AUTOSAR XML (schema 4-0-3)
package /ComponentTypes
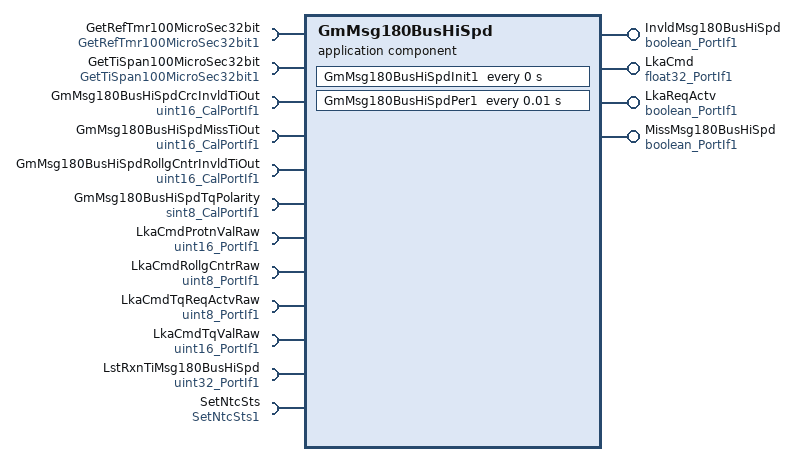
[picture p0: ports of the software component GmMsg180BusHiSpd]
  application sw component type GmMsg180BusHiSpd
    4 x provide port:
      InvldMsg180BusHiSpd: nonqueued-sender-com-spec{data-element=Logl, init-value=0}, provided-interface=boolean_PortIf1
      LkaCmd: nonqueued-sender-com-spec{data-element=Val, init-value=0}, provided-interface=float32_PortIf1
      LkaReqActv: nonqueued-sender-com-spec{data-element=Logl, init-value=0}, provided-interface=boolean_PortIf1
      MissMsg180BusHiSpd: nonqueued-sender-com-spec{data-element=Logl, init-value=0}, provided-interface=boolean_PortIf1
    12 x require port:
      GetRefTmr100MicroSec32bit: required-interface=GetRefTmr100MicroSec32bit1
      GetTiSpan100MicroSec32bit: required-interface=GetTiSpan100MicroSec32bit1
      GmMsg180BusHiSpdCrcInvldTiOut: parameter-require-com-spec{init-value=1000, parameter=Val}, required-interface=uint16_CalPortIf1
      GmMsg180BusHiSpdMissTiOut: parameter-require-com-spec{init-value=500, parameter=Val}, required-interface=uint16_CalPortIf1
      GmMsg180BusHiSpdRollgCntrInvldTiOut: parameter-require-com-spec{init-value=500, parameter=Val}, required-interface=uint16_CalPortIf1
      GmMsg180BusHiSpdTqPolarity: parameter-require-com-spec{init-value=1, parameter=Val}, required-interface=sint8_CalPortIf1
      LkaCmdProtnValRaw: nonqueued-receiver-com-spec{data-element=Val, filter=data-filter-type=ALWAYS, init-value=0}, required-interface=uint16_PortIf1
      LkaCmdRollgCntrRaw: nonqueued-receiver-com-spec{data-element=Val, filter=data-filter-type=ALWAYS, init-value=0}, required-interface=uint8_PortIf1
      LkaCmdTqReqActvRaw: nonqueued-receiver-com-spec{data-element=Val, filter=data-filter-type=ALWAYS, init-value=0}, required-interface=uint8_PortIf1
      LkaCmdTqValRaw: nonqueued-receiver-com-spec{data-element=Val, filter=data-filter-type=ALWAYS, init-value=0}, required-interface=uint16_PortIf1
      LstRxnTiMsg180BusHiSpd: nonqueued-receiver-com-spec{data-element=Val, filter=data-filter-type=ALWAYS, init-value=0}, required-interface=uint32_PortIf1
      SetNtcSts: required-interface=SetNtcSts1
    behavior GmMsg180BusHiSpd_InternalBehavior: data-type-mapping=Nexteer
      ar-typed-per-instance-memorys:
        8 x data, all with sw-calibration-access=READ-ONLY:
          GmMsg180BusHiSpdInvldCrcTmr: type=uint32
          GmMsg180BusHiSpdInvldRollgCntrTmr: type=uint32
          GmMsg180BusHiSpdPrevInvld: type=boolean
          GmMsg180BusHiSpdPrevRollgCntrVal: type=uint8
          GmMsg180BusHiSpdPrevRxnTi: type=uint32
          GmMsg180BusHiSpdPrevTqCmd: type=float32
          GmMsg180BusHiSpdPrevTqReq: type=boolean
          GmMsg180BusHiSpdRollgCntrRst: type=boolean
      timing event GmMsg180BusHiSpd_InitEvent: start-on-event=GmMsg180BusHiSpdInit1, period=0
      timing event TMT_GM0C9HSPer1: start-on-event=GmMsg180BusHiSpdPer1, period=0.01
      runnable GmMsg180BusHiSpdInit1
      runnable GmMsg180BusHiSpdPer1
        data-receive-point-by-arguments:
          5 x access:
            REC_LkaCmdProtnValRaw_Val: accessed-variable=LkaCmdProtnValRaw.Val
            REC_LkaCmdRollgCntrRaw_Val: accessed-variable=LkaCmdRollgCntrRaw.Val
            REC_LkaCmdTqReqActvRaw_Val: accessed-variable=LkaCmdTqReqActvRaw.Val
            REC_LkaCmdTqValRaw_Val: accessed-variable=LkaCmdTqValRaw.Val
            REC_Msg0C9HSLstRxnTi_Val: accessed-variable=LstRxnTiMsg180BusHiSpd.Val
        data-send-points:
          4 x access:
            SEND_InvldMsg180BusHiSpd_Logl: accessed-variable=InvldMsg180BusHiSpd.Logl
            SEND_LkaCmd_Val: accessed-variable=LkaCmd.Val
            SEND_LkaReqActv_Logl: accessed-variable=LkaReqActv.Logl
            SEND_MissMsg180BusHiSpd_Logl: accessed-variable=MissMsg180BusHiSpd.Logl
        sync call SC_GetRefTmr100MicroSec32bit_Oper: operation=GetRefTmr100MicroSec32bit.Oper, timeout=0
        sync call SC_GetTiSpan100MicroSec32bit_Oper: operation=GetTiSpan100MicroSec32bit.Oper, timeout=0
        sync call SC_SetNtcSts_Oper: operation=SetNtcSts.Oper, timeout=0
  swc implementation GmMsg180BusHiSpd_Implementation: behavior=GmMsg180BusHiSpd_InternalBehavior
    code-descriptors:
      code Default: artifact-descriptors=autosar-engineering-object={short-label=Default, category=SWSRC}
